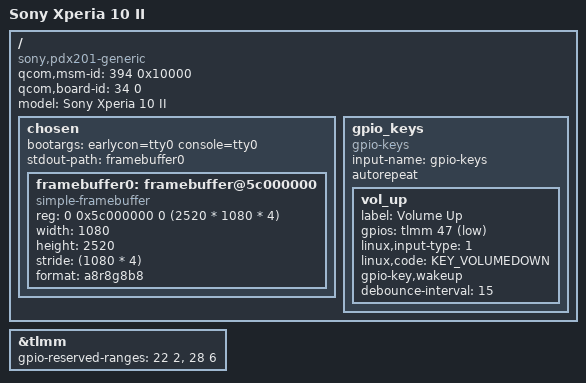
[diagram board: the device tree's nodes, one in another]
// SPDX-License-Identifier: BSD-3-Clause
/*
 * Copyright (c) 2021, Martin Botka <martin.botka@somainline.org>
 */

/dts-v1/;

#include "sm6125.dtsi"
#include <dt-bindings/gpio/gpio.h>
#include <dt-bindings/input/input.h>
#include <dt-bindings/input/gpio-keys.h>

/ {
	/* required for bootloader to select correct board */
	qcom,msm-id = <394 0x10000>; /* sm6125 v1 */
	qcom,board-id = <34 0>;

	model = "Sony Xperia 10 II";
	compatible = "sony,pdx201-generic", "qcom,sm6125";

	/* This part enables graphical output via bootloader-enabled display */
	chosen {
		bootargs = "earlycon=tty0 console=tty0";
		stdout-path = "framebuffer0";
		#address-cells = <2>;
		#size-cells = <2>;
		ranges;

		framebuffer0: framebuffer@5c000000 {
			compatible = "simple-framebuffer";
			reg = <0 0x5c000000 0 (2520 * 1080 * 4)>;
			width = <1080>;
			height = <2520>;
			stride = <(1080 * 4)>;
			format = "a8r8g8b8";
			status= "okay";
		};
	};

	gpio_keys {
		status = "okay";
		compatible = "gpio-keys";
		input-name = "gpio-keys";
		#address-cells = <1>;
		#size-cells = <0>;
		autorepeat;

		vol_up {
			label = "Volume Up";
			gpios = <&tlmm 47 GPIO_ACTIVE_LOW>;
			linux,input-type = <1>;
			linux,code = <KEY_VOLUMEDOWN>;
			gpio-key,wakeup;
			debounce-interval = <15>;
		};
	};
};

&tlmm {
	gpio-reserved-ranges = <22 2>, <28 6>;
};
